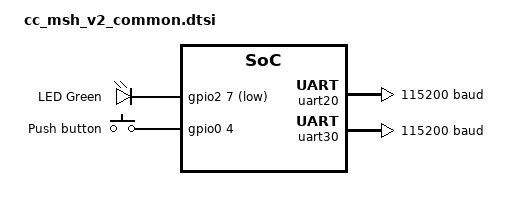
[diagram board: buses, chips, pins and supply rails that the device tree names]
/*
 * Copyright (c) 2025 Classified Cycling BV
 *
 * SPDX-License-Identifier: Apache-2.0
 */

#include "cc_msh_v2_common_pinctrl.dtsi"

/ {
	leds {
		compatible = "gpio-leds";
		led0: led_0 {
			gpios = <&gpio2 7 GPIO_ACTIVE_LOW>;
			label = "LED Green";
		};
	};

	buttons {
		compatible = "gpio-keys";
		button0: button_0 {
			gpios = <&gpio0 4 (GPIO_PULL_DOWN | GPIO_ACTIVE_HIGH)>;
			label = "Push button";
			zephyr,code = <INPUT_KEY_0>;
		};
	};

	aliases {
		led0 = &led0;
		sw0 = &button0;
		watchdog0 = &wdt31;
	};
};

&uart20 {
	current-speed = <115200>;
	pinctrl-0 = <&uart20_default>;
	pinctrl-1 = <&uart20_sleep>;
	pinctrl-names = "default", "sleep";
};

&uart30 {
	current-speed = <115200>;
	pinctrl-0 = <&uart30_default>;
	pinctrl-1 = <&uart30_sleep>;
	pinctrl-names = "default", "sleep";
};
